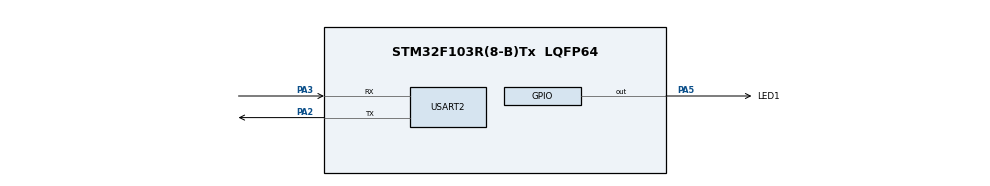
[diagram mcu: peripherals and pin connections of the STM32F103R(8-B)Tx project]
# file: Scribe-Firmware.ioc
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FREERTOS.Tasks01=HeartbeatTask,48,128,StartHeartbeatTask,Default,NULL,Dynamic,NULL,NULL
FREERTOS.configTOTAL_HEAP_SIZE=8192
FREERTOS.configUSE_NEWLIB_REENTRANT=1
Mcu.Family=STM32F1
Mcu.Name=STM32F103R(8-B)Tx
Mcu.Package=LQFP64
NVIC.PriorityGroup=NVIC_PRIORITYGROUP_4
NVIC.TIM4_IRQn=true\:15\:0\:false\:false\:true\:false\:false\:true\:true
NVIC.TimeBase=TIM4_IRQn
NVIC.TimeBaseIP=TIM4
PA13.Mode=Serial_Wire
PA13.Signal=SYS_JTMS-SWDIO
PA14.Mode=Serial_Wire
PA14.Signal=SYS_JTCK-SWCLK
PA2.Mode=Asynchronous
PA2.Signal=USART2_TX
PA3.Mode=Asynchronous
PA3.Signal=USART2_RX
PA5.GPIO_Label=LED1
PA5.Signal=GPIO_Output
ProjectManager.HeapSize=0x200
ProjectManager.StackSize=0x400
ProjectManager.TargetToolchain=STM32CubeIDE
RCC.APB1Freq_Value=8000000
RCC.APB2Freq_Value=8000000
USART2.VirtualMode=VM_ASYNC
VP_FREERTOS_VS_CMSIS_V2.Mode=CMSIS_V2
VP_SYS_VS_tim4.Mode=TIM4
board=custom

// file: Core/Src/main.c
/* USER CODE BEGIN Header */
/**
  ******************************************************************************
  * @file           : main.c
  * @brief          : Main program body
  ******************************************************************************
  * @attention
  *
  * Copyright (c) 2025 STMicroelectronics.
  * All rights reserved.
  *
  * This software is licensed under terms that can be found in the LICENSE file
  * in the root directory of this software component.
  * If no LICENSE file comes with this software, it is provided AS-IS.
  *
  ******************************************************************************
  */
/* USER CODE END Header */
#include "main.h"
#include "cmsis_os.h"
#include "usart.h"
#include "gpio.h"

/* USER CODE BEGIN Includes */
#include "task_ads1115.h"
#include "FreeRTOS.h" // This is directly accessing FreeRTOS, not the CMSIS_v2 wrapper
#include "task.h"
/* USER CODE END Includes */

void SystemClock_Config(void);
void MX_FREERTOS_Init(void);

int main(void)
{

  /* MCU Configuration--------------------------------------------------------*/

  /* Reset of all peripherals, Initializes the Flash interface and the Systick. */
  HAL_Init();

  /* Configure the system clock */
  SystemClock_Config();

  /* Initialize all configured peripherals */
  MX_GPIO_Init();
  MX_USART2_UART_Init();
  /* USER CODE BEGIN 2 */

  /* Initialize and create all tasks */
  ADS1115_Tasks_Init();  // Re-enabled with increased heap size

  // We could use vTaskStartScheduler() here, but to keep things compatible with autogenerated stm32 code, we use osKernelStart()

  /* USER CODE END 2 */

  /* Init scheduler */
  osKernelInitialize();  /* Call init function for freertos objects (in cmsis_os2.c) */
  MX_FREERTOS_Init();

  /* Start scheduler */
  osKernelStart();

  /* We should never get here as control is now taken by the scheduler */

  /* Infinite loop */
  while (1)
  {

  }
}

void SystemClock_Config(void)
{
  RCC_OscInitTypeDef RCC_OscInitStruct = {0};
  RCC_ClkInitTypeDef RCC_ClkInitStruct = {0};

  /** Initializes the RCC Oscillators according to the specified parameters
  * in the RCC_OscInitTypeDef structure.
  */
  RCC_OscInitStruct.OscillatorType = RCC_OSCILLATORTYPE_HSI;
  RCC_OscInitStruct.HSIState = RCC_HSI_ON;
  RCC_OscInitStruct.HSICalibrationValue = RCC_HSICALIBRATION_DEFAULT;
  RCC_OscInitStruct.PLL.PLLState = RCC_PLL_NONE;
  if (HAL_RCC_OscConfig(&RCC_OscInitStruct) != HAL_OK)
  {
    Error_Handler();
  }

  /** Initializes the CPU, AHB and APB buses clocks
  */
  RCC_ClkInitStruct.ClockType = RCC_CLOCKTYPE_HCLK|RCC_CLOCKTYPE_SYSCLK
                              |RCC_CLOCKTYPE_PCLK1|RCC_CLOCKTYPE_PCLK2;
  RCC_ClkInitStruct.SYSCLKSource = RCC_SYSCLKSOURCE_HSI;
  RCC_ClkInitStruct.AHBCLKDivider = RCC_SYSCLK_DIV1;
  RCC_ClkInitStruct.APB1CLKDivider = RCC_HCLK_DIV1;
  RCC_ClkInitStruct.APB2CLKDivider = RCC_HCLK_DIV1;

  if (HAL_RCC_ClockConfig(&RCC_ClkInitStruct, FLASH_LATENCY_0) != HAL_OK)
  {
    Error_Handler();
  }
}

void HAL_TIM_PeriodElapsedCallback(TIM_HandleTypeDef *htim)
{
  if (htim->Instance == TIM4)
  {
    HAL_IncTick();
  }
}

void Error_Handler(void)
{
  __disable_irq();
  while (1)
  {
  }
}

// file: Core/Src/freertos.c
/* USER CODE BEGIN Header */
/**
  ******************************************************************************
  * File Name          : freertos.c
  * Description        : Code for freertos applications
  ******************************************************************************
  * @attention
  *
  * Copyright (c) 2025 STMicroelectronics.
  * All rights reserved.
  *
  * This software is licensed under terms that can be found in the LICENSE file
  * in the root directory of this software component.
  * If no LICENSE file comes with this software, it is provided AS-IS.
  *
  ******************************************************************************
  */
/* USER CODE END Header */

#include "FreeRTOS.h"
#include "task.h"
#include "main.h"
#include "cmsis_os.h"

/* USER CODE BEGIN Variables */

// NOTE:
// osThreadId_t is a typedef in cmsis_os2.h
// It is a wrapper around FreeRTOS TaskHandle_t
// So, for all my custom tasks I use TaskHandle_t while here STM32 CubeIDE uses osThreadId_t

/* USER CODE END Variables */
/* Definitions for HeartbeatTask */
osThreadId_t HeartbeatTaskHandle;
const osThreadAttr_t HeartbeatTask_attributes = {
  .name = "HeartbeatTask",
  .stack_size = 128 * 4,
  .priority = (osPriority_t) osPriorityRealtime,
};

void StartHeartbeatTask(void *argument);

void MX_FREERTOS_Init(void); /* (MISRA C 2004 rule 8.1) */

void MX_FREERTOS_Init(void) {
  /* USER CODE BEGIN Init */
  /* NOTE: This function is deprecated - tasks are now created manually */
  /* USER CODE END Init */

  /* Create the thread(s) */
  /* creation of HeartbeatTask */
  HeartbeatTaskHandle = osThreadNew(StartHeartbeatTask, NULL, &HeartbeatTask_attributes);

  /* USER CODE BEGIN RTOS_THREADS */
  /* Tasks are now created manually in individual task files */
  /* USER CODE END RTOS_THREADS */

}

void StartHeartbeatTask(void *argument)
{
  /* USER CODE BEGIN StartHeartbeatTask */
  /* Infinite loop */
  for(;;)
  {
    HAL_GPIO_TogglePin(LED1_GPIO_Port, LED1_Pin);  // Toggle LED pin
    osDelay(1000); // Only use osDelay() here for cmsis tasks, everywhere else use raw FreeRTOS vTaskDelay()
  }
  /* USER CODE END StartHeartbeatTask */
}
